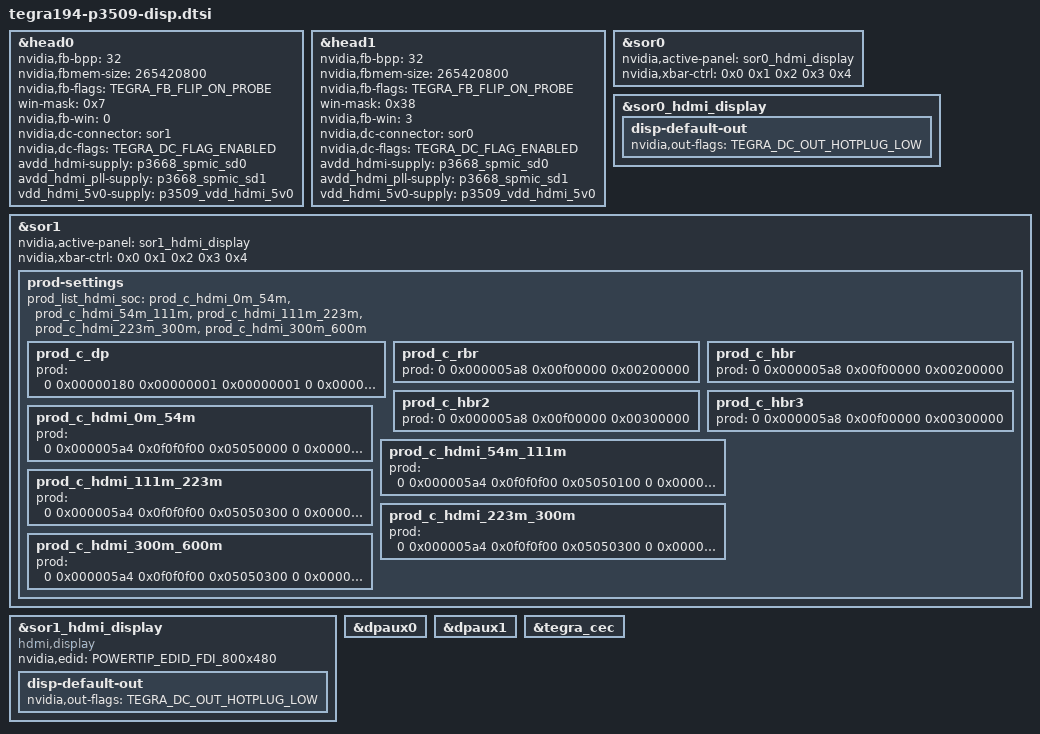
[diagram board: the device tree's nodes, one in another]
/*
 * tegra194-p3509-disp.dtsi:
 *
 * Copyright (c) 2019, NVIDIA CORPORATION.  All rights reserved.
 *
 * This program is free software; you can redistribute it and/or modify
 * it under the terms of the GNU General Public License as published by
 * the Free Software Foundation; version 2 of the License.
 *
 * This program is distributed in the hope that it will be useful, but WITHOUT
 * ANY WARRANTY; without even the implied warranty of MERCHANTABILITY or
 * FITNESS FOR A PARTICULAR PURPOSE.  See the GNU General Public License for
 * more details.
 *
 *
 * t194 jakku product uses 2 display heads out of the 4 available on t194:
 *	fb0: Head0->SOR1->HDMI
 *	fb1: Head1->SOR0->DP
 * Each display head is assigned three windows each.
 */

#include <dt-bindings/display/tegra-dc.h>
#include <dt-bindings/display/tegra-panel.h>
#include <t19x-common-platforms/tegra194-hdmi.dtsi>
#include <t19x-common-platforms/tegra194-dp.dtsi>
#include "tegra194-fixed-regulator-p3509-0000-a00.dtsi"
#include "tegra194-spmic-p3668.dtsi"

#define POWERTIP_EDID_FDI_800x480 \
[00 ff ff ff ff ff ff 00 04 81 04 00 01 00 00 00\
 01 11 01 03 80 0f 08 00 02 42 cc 8f 52 57 99 23\
 12 4c 52 00 00 00 01 01 01 01 01 01 01 01 01 01\
 01 01 01 01 01 01 50 0f 20 c8 30 e0 50 10 9a 0a\
 9a 00 e8 30 32 00 00 1e 00 00 00 10 00 00 00 00\
 00 00 00 00 00 00 00 00 00 00 00 00 00 10 00 00\
 00 00 00 00 00 00 00 00 00 00 00 00 00 00 00 10\
 00 00 00 00 00 00 00 00 00 00 00 00 00 00 00 7e]

&head0 {
	status = "okay";
	nvidia,fb-bpp = <32>;
	nvidia,fbmem-size = <265420800>; /* 8K (7680*4320) 32bpp double buffered */
	nvidia,fb-flags = <TEGRA_FB_FLIP_ON_PROBE>;
	win-mask = <0x7>;
	nvidia,fb-win = <0>;
	nvidia,dc-connector = <&sor1>;
	nvidia,dc-flags = <TEGRA_DC_FLAG_ENABLED>;
	avdd_hdmi-supply = <&p3668_spmic_sd0>; /* 1v0 */
	avdd_hdmi_pll-supply = <&p3668_spmic_sd1>; /* 1v8 */
	vdd_hdmi_5v0-supply = <&p3509_vdd_hdmi_5v0>; /* 5v0 */
};

&head1 {
	status = "okay";
	nvidia,fb-bpp = <32>;
	nvidia,fbmem-size = <265420800>; /* 8K (7680*4320) 32bpp double buffered */
	nvidia,fb-flags = <TEGRA_FB_FLIP_ON_PROBE>;
	win-mask = <0x38>;
	nvidia,fb-win = <3>;
	nvidia,dc-connector = <&sor0>;
	nvidia,dc-flags = <TEGRA_DC_FLAG_ENABLED>;
	//vdd-dp-pwr-supply = <&p3668_spmic_sd0>;
	//avdd-dp-pll-supply = <&p3668_spmic_sd1>;
	//vdd-edp-sec-mode-supply = <&battery_reg>;
	//vdd-dp-pad-supply = <&battery_reg>;
	avdd_hdmi-supply = <&p3668_spmic_sd0>; /* 1v0 */
	avdd_hdmi_pll-supply = <&p3668_spmic_sd1>; /* 1v8 */
	vdd_hdmi_5v0-supply = <&p3509_vdd_hdmi_5v0>; /* 5v0 */
};

&sor0 {
	status = "okay";
	nvidia,active-panel = <&sor0_hdmi_display>;
	nvidia,xbar-ctrl = <0x0 0x1 0x2 0x3 0x4>;
};

&sor0_hdmi_display {
	status = "okay";
	disp-default-out {
		nvidia,out-flags = <TEGRA_DC_OUT_HOTPLUG_LOW>;
	};
};

&sor1 {
	status = "okay";
	nvidia,active-panel = <&sor1_hdmi_display>;
	nvidia,xbar-ctrl = <0x0 0x1 0x2 0x3 0x4>;
	prod-settings {
		#prod-cells = <4>;
		prod_list_hdmi_soc = "prod_c_hdmi_0m_54m","prod_c_hdmi_54m_111m","prod_c_hdmi_111m_223m","prod_c_hdmi_223m_300m","prod_c_hdmi_300m_600m";
		prod_c_dp {
			prod = <
				0 0x00000180 0x00000001 0x00000001		//SOR_NV_PDISP_SOR_DP_SPARE0_0	00:00=SEQ_ENABLE		0x1
				0 0x000005a4 0x0f0f0f00 0x05050300		//SOR_NV_PDISP_SOR_PLL0_0	27:24=ICHPMP			0x5
										//				19:16=FILTER			0x5
										//				11:08=VCOCAP			0x3
				0 0x000005a8 0x00000100 0x00000100		//SOR_NV_PDISP_SOR_PLL1_0	08:08=TMDS_TERM			0x1
				0 0x000005ac 0xf000ff00 0x00000000		//SOR_NV_PDISP_SOR_PLL2_0	31:28=PLL_MDIV			0x0
										//				15:08=PLL_NDIV			0x0
				0 0x000005b0 0x00000ff0 0x00000440		//SOR_NV_PDISP_SOR_PLL3_0	11:08=AVDD10_LEVEL		0x4
										//				07:04=AVDD14_LEVEL		0x4
				0 0x000005b4 0x00400000 0x00000000		//SOR_NV_PDISP_SOR_PLL4_0	22:22=ENB_LCKDET		0x0
				0 0x000005e4 0x00003b80 0x00001a00>;		//SOR_NV_PDISP_SOR_PLL5_0	13:11=PLL_SEL_TIMER		0x3
										//				09:07=PLL_LOCKDET2_SETUPN	0x4
		};
		prod_c_rbr {
			prod = <
				0 0x000005a8 0x00f00000 0x00200000>;		//SOR_NV_PDISP_SOR_PLL1_0	23:20=LOADADJ			0x2
		};
		prod_c_hbr {
			prod = <
				0 0x000005a8 0x00f00000 0x00200000>;		//SOR_NV_PDISP_SOR_PLL1_0	23:20=LOADADJ			0x2
		};
		prod_c_hbr2 {
			prod = <
				0 0x000005a8 0x00f00000 0x00300000>;		//SOR_NV_PDISP_SOR_PLL1_0	23:20=LOADADJ			0x3
		};
		prod_c_hbr3 {
			prod = <
				0 0x000005a8 0x00f00000 0x00300000>;		//SOR_NV_PDISP_SOR_PLL1_0	23:20=LOADADJ			0x3
		};
		prod_c_hdmi_0m_54m {
			prod = <
				0 0x000005a4 0x0f0f0f00 0x05050000              //SOR_NV_PDISP_SOR_PLL0
				0 0x000005a8 0x00f00100 0x00300100              //SOR_NV_PDISP_SOR_PLL1
				0 0x000005b0 0xff000ff0 0x38000440              //SOR_NV_PDISP_SOR_PLL3
				0 0x000005e4 0x00003f80 0x00002a00              //SOR_NV_PDISP_SOR_PLL5_0
				0 0x00000138 0xffffffff 0x06060606              //SOR_NV_PDISP_SOR_LANE_DRIVE_CURRENT0_0
				0 0x00000148 0xffffffff 0x00000000              //SOR_NV_PDISP_SOR_LANE_PREEMPHASIS0_0
				0 0x000005b8 0x0040ff00 0x00400000>;            //SOR_NV_PDISP_SOR_DP_PADCTL0
		};
		prod_c_hdmi_54m_111m {
			prod = <
				0 0x000005a4 0x0f0f0f00 0x05050100              //SOR_NV_PDISP_SOR_PLL0
				0 0x000005a8 0x00f00100 0x00300100              //SOR_NV_PDISP_SOR_PLL1
				0 0x000005b0 0xff000ff0 0x38000440              //SOR_NV_PDISP_SOR_PLL3
				0 0x000005e4 0x00003f80 0x00002200              //SOR_NV_PDISP_SOR_PLL5_0
				0 0x00000138 0xffffffff 0x06060606              //SOR_NV_PDISP_SOR_LANE_DRIVE_CURRENT0_0
				0 0x00000148 0xffffffff 0x00000000              //SOR_NV_PDISP_SOR_LANE_PREEMPHASIS0_0
				0 0x000005b8 0x0040ff00 0x00400000>;            //SOR_NV_PDISP_SOR_DP_PADCTL0
		};
		prod_c_hdmi_111m_223m {
			prod = <
				0 0x000005a4 0x0f0f0f00 0x05050300              //SOR_NV_PDISP_SOR_PLL0
				0 0x000005a8 0x00f00100 0x00300100              //SOR_NV_PDISP_SOR_PLL1
				0 0x000005b0 0xff000ff0 0x38000440              //SOR_NV_PDISP_SOR_PLL3
				0 0x000005e4 0x00003f80 0x00001a00              //SOR_NV_PDISP_SOR_PLL5_0
				0 0x00000138 0xffffffff 0x06060606              //SOR_NV_PDISP_SOR_LANE_DRIVE_CURRENT0_0
				0 0x00000148 0xffffffff 0x00000000              //SOR_NV_PDISP_SOR_LANE_PREEMPHASIS0_0
				0 0x000005b8 0x0040ff00 0x00400000>;            //SOR_NV_PDISP_SOR_DP_PADCTL0
		};
		prod_c_hdmi_223m_300m {
			prod = <
				0 0x000005a4 0x0f0f0f00 0x05050300              //SOR_NV_PDISP_SOR_PLL0
				0 0x000005a8 0x00f00100 0x00300100              //SOR_NV_PDISP_SOR_PLL1
				0 0x000005b0 0xff000ff0 0x38000440              //SOR_NV_PDISP_SOR_PLL3
				0 0x000005e4 0x00003f80 0x00001a00              //SOR_NV_PDISP_SOR_PLL5_0
				0 0x00000138 0xffffffff 0x06060606              //SOR_NV_PDISP_SOR_LANE_DRIVE_CURRENT0_0
				0 0x00000148 0xffffffff 0x00000000              //SOR_NV_PDISP_SOR_LANE_PREEMPHASIS0_0
				0 0x000005b8 0x0040ff00 0x00404000>;            //SOR_NV_PDISP_SOR_DP_PADCTL0
		};
		prod_c_hdmi_300m_600m {
			prod = <
				0 0x000005a4 0x0f0f0f00 0x05050300              //SOR_NV_PDISP_SOR_PLL0
				0 0x000005a8 0x00f00100 0x00300100              //SOR_NV_PDISP_SOR_PLL1
				0 0x000005b0 0xff000ff0 0x38000440              //SOR_NV_PDISP_SOR_PLL3
				0 0x000005e4 0x00003f80 0x00001a00              //SOR_NV_PDISP_SOR_PLL5_0
				0 0x00000138 0xffffffff 0x06060606              //SOR_NV_PDISP_SOR_LANE_DRIVE_CURRENT0_0
				0 0x00000148 0xffffffff 0x00000000              //SOR_NV_PDISP_SOR_LANE_PREEMPHASIS0_0
				0 0x000005b8 0x0040ff00 0x00406000>;            //SOR_NV_PDISP_SOR_DP_PADCTL0
		};
	};
};

&sor1_hdmi_display {
	status = "okay";
	compatible = "hdmi,display";
	nvidia,edid = POWERTIP_EDID_FDI_800x480;
	disp-default-out {
		nvidia,out-flags = <TEGRA_DC_OUT_HOTPLUG_LOW>;
	};
};

&dpaux0 {
	status = "okay";
};

&dpaux1 {
	status = "okay";
};

&tegra_cec {
	status = "okay";
};
